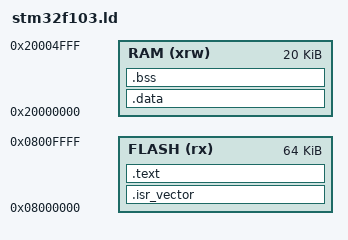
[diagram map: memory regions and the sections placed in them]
/* STM32F103C8 (Blue Pill) ? 64KB Flash, 20KB RAM */
ENTRY(Reset_Handler)

MEMORY
{
    FLASH (rx)  : ORIGIN = 0x08000000, LENGTH = 64K
    RAM   (xrw) : ORIGIN = 0x20000000, LENGTH = 20K
}

_estack = ORIGIN(RAM) + LENGTH(RAM);

SECTIONS
{
    .isr_vector :
    {
        KEEP(*(.isr_vector))
        . = ALIGN(4);
    } > FLASH

    .text :
    {
        *(.text*)
        *(.rodata*)
        . = ALIGN(4);
        _etext = .;
    } > FLASH

    .data : AT(ADDR(.text) + SIZEOF(.text))
    {
        _sdata = .;
        *(.data*)
        . = ALIGN(4);
        _edata = .;
    } > RAM

    .bss :
    {
        _sbss = .;
        __bss_start__ = _sbss;
        *(.bss*)
        *(COMMON)
        . = ALIGN(4);
        _ebss = .;
        __bss_end__ = _ebss;
    } > RAM

    /DISCARD/ : { *(.ARM.exidx*) }
}
